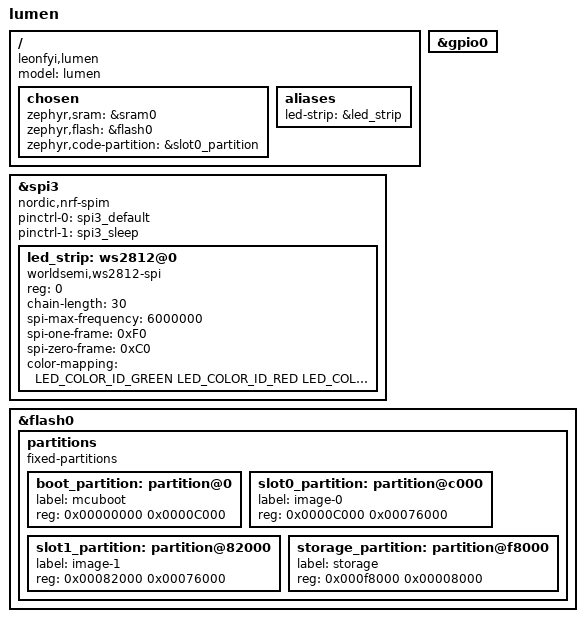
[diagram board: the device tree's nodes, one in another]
/*
 * Copyright (c) 2021 Nordic Semiconductor ASA
 * Copyright (c) 2023 Leon Rinkel
 * SPDX-License-Identifier: Apache-2.0
 */

/dts-v1/;

#include <nordic/nrf52840_qiaa.dtsi>
#include <zephyr/dt-bindings/led/led.h>
#include "lumen-pinctrl.dtsi"

/ {
	model = "lumen";
	compatible = "leonfyi,lumen";

	chosen {
		zephyr,sram = &sram0;
		zephyr,flash = &flash0;
		zephyr,code-partition = &slot0_partition;
	};

	aliases {
		led-strip = &led_strip;
	};
};

&gpio0 {
	status = "okay";
};

&spi3 {
	compatible = "nordic,nrf-spim";
	status = "okay";
	pinctrl-0 = <&spi3_default>;
	pinctrl-1 = <&spi3_sleep>;
	pinctrl-names = "default", "sleep";

	led_strip: ws2812@0 {
		compatible = "worldsemi,ws2812-spi";
		reg = <0>;
		chain-length = <30>;

		/* Timing for SK6812-type LEDs */
		spi-max-frequency = <6000000>; /* 1 / 6MHz = 167ns */
		spi-one-frame = <0xF0>;  /* 167ns * 4 = 0.668us */
		spi-zero-frame = <0xC0>; /* 167ns * 2 = 0.334us */

		color-mapping = <LED_COLOR_ID_GREEN
				 LED_COLOR_ID_RED
				 LED_COLOR_ID_BLUE
				 LED_COLOR_ID_WHITE>;
	};
};

&flash0 {
	partitions {
		compatible = "fixed-partitions";
		#address-cells = <1>;
		#size-cells = <1>;

		boot_partition: partition@0 {
			label = "mcuboot";
			reg = <0x00000000 0x0000C000>;
		};
		slot0_partition: partition@c000 {
			label = "image-0";
			reg = <0x0000C000 0x00076000>;
		};
		slot1_partition: partition@82000 {
			label = "image-1";
			reg = <0x00082000 0x00076000>;
		};

		/*
		 * The flash starting at 0x000f8000 and ending at
		 * 0x000fffff is reserved for use by the application.
		 */

		/*
		 * Storage partition will be used by FCB/LittleFS/NVS
		 * if enabled.
		 */
		storage_partition: partition@f8000 {
			label = "storage";
			reg = <0x000f8000 0x00008000>;
		};
	};
};
